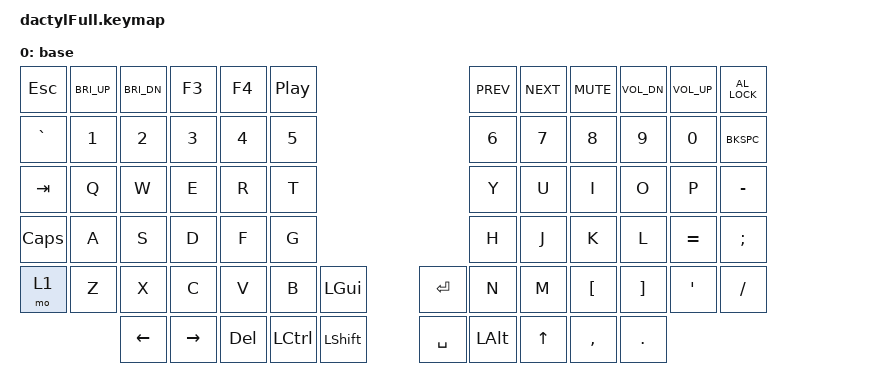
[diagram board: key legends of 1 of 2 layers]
#include <behaviors.dtsi>
#include <dt-bindings/zmk/keys.h>

#define DEFAULT 0
#define LOWER 1

/{
    keymap{
        compatible = "zmk,keymap";

        default_layer {
            display-name = "base";
// ------------------------------------------------------------------------------------------------------------
// |  ESC  |brght| drk |  f3  | f4   | pause|                                    | back | next  |  mute |voldwn|  volup|   PWR |
// |  `    |  1  |  2  |  3   |  4   |  5   |                                    |  6   |  7    |  8    |  9   |   0   | BKSPC |
// |  TAB  |  Q  |  W  |  E   |  R   |  T   |                                    |  Y   |  U    |  I    |  O   |   P   |   -   |
// |   CAP |  A  |  S  |  D   |  F   |  G   |                                    |  H   |  J    |  K    |  L   |   =   |    ;  |
// |  FN   |  Z  |  X  |  C   |  V   |  B   |LEFT GUI|                   |  RTRN |  N   |  M    |L-BRCK |R-BRCK| QUOTE | /     |
//               | LEFT|RIGHT|    del       |ctrl    |LSHIFT|      |space| ALT   | UP           |  ,    |  .   | 
//                                                             
            bindings = <
    &kp ESC &kp C_BRI_UP &kp C_BRI_DN &kp F3 &kp F4 &kp C_PP                      &kp C_PREV &kp C_NEXT &kp C_MUTE &kp C_VOL_DN &kp C_VOL_UP &kp C_AL_LOCK
    &kp GRAVE &kp N1 &kp N2 &kp N3 &kp N4 &kp N5                                  &kp N6 &kp N7 &kp N8 &kp N9 &kp N0 &kp BKSPC
    &kp TAB &kp Q &kp W &kp E &kp R &kp T                                         &kp Y &kp U &kp I &kp O &kp P &kp MINUS
    &kp CAPS &kp A &kp S &kp D &kp F &kp G                                        &kp H &kp J &kp K &kp L &kp EQUAL &kp SEMI
    &mo 1 &kp Z &kp X &kp C &kp V &kp B  &kp LGUI                                   &kp RET &kp N &kp M &kp LBKT &kp RBKT &kp SQT &kp SLASH
                 &kp LEFT &kp RIGHT  &kp DEL &kp LCTRL &kp LSHIFT  &kp SPACE &kp LALT &kp UP      &kp COMMA &kp DOT
                                                               

            >;

        };
        lower_layer{
            display-name = "function";
// ------------------------------------------------------------------------------------------------------------
// |   f12 |F1   | F2  |  f3  | f4   | f5   |                                    | f6   | f7    |  f8   |f9    |  f10  |   f11 |
// |       |     |     |      |      |      |                                    |  BT 1| BT 2  | BT 3  | BT 4 |       |       |
// |       |     |     |      |      |      |                                    |      |       |       |      |       |       |
// |       |     |     |      |      |      |                                    |BT CLR|       |       |      |       |       |
// |       |     |     |      |      |      |                                    |      |       |       |      |       |       |
//               |     |      |             |        | SHIFT  |  |  \  | |       |     DWN      |       |      | 
//                                          |        |                   |  | 
            bindings = <
    &kp F12 &kp F1 &kp F2 &kp F3 &kp F4 &kp f5                                  &kp F6  &kp F7  &kp F8  &kp F9  &kp F10  &kp f11
    &trans &trans &trans &trans &trans &trans                                   &bt BT_SEL 1 &bt BT_SEL 2 &bt BT_SEL 3 &bt BT_SEL 4 &trans &trans 
    &trans &trans &trans &trans &trans &trans                                   &trans &trans &trans &trans &trans &trans 
    &trans &trans &trans &trans &trans &trans                                   &bt BT_CLR &trans &trans &trans &trans &trans 
    &trans &trans &trans &trans &trans &trans &trans                           &trans  &trans &trans &trans &trans &trans &trans 
                         &trans &trans &trans &trans &kp LSHIFT   &kp BACKSLASH &kp DOWN            &trans &trans 
                                                                    
            >;
        };
    };
};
